VERSION ""

NS_ :

BS_:

BU_: HMI1 HMI2 VCU BMS MCU

BO_ 3221225472 VECTOR__INDEPENDENT_SIG_MSG: 0 Vector__XXX
 SG_ RangeReportVal : 16|8@1+ (1,0) [0|0] "km"  HMI1
 SG_ AverageReportVal : 24|8@1+ (1,0) [0|0] "km/kwh"  HMI1

BO_ 1984 HMI1Heartbeat: 2 HMI1
 SG_ HMI1Version : 0|16@1+ (1,0) [0|65535] ""  VCU

BO_ 1968 VCUHeartbeat: 2 VCU
 SG_ VCUVersion : 0|16@1+ (1,0) [0|65535] "" Vector__XXX

BO_ 2000 HMI2Heartbeat: 2 HMI2
 SG_ HMI2Version : 0|16@1+ (1,0) [0|65535] ""  VCU

BO_ 42 VCUSwitchControl: 8 VCU
 SG_ ABSState : 0|1@1+ (1,0) [0|1] ""  HMI1
 SG_ MirroringState : 1|1@1+ (1,0) [0|1] ""  HMI1
 SG_ LampState : 2|1@1+ (1,0) [0|1] ""  HMI1
 SG_ ErrorState : 3|1@1+ (1,0) [0|1] ""  HMI1
 SG_ OverheatState : 4|1@1+ (1,0) [0|1] ""  HMI1
 SG_ FingerState : 5|1@1+ (1,0) [0|1] ""  HMI1
 SG_ RemoteState : 6|1@1+ (1,0) [0|1] ""  HMI1
 SG_ DaylightState : 7|1@1+ (1,0) [0|1] ""  HMI1
 SG_ SeinLeftState : 8|1@1+ (1,0) [0|1] ""  HMI1
 SG_ SeinRightState : 9|1@1+ (1,0) [0|1] ""  HMI1
 SG_ HbarReverseState : 10|1@1+ (1,0) [0|1] ""  HMI1
 SG_ DriveMode : 16|2@1+ (1,0) [0|2] ""  HMI1
 SG_ TripMode : 18|2@1+ (1,0) [0|2] ""  HMI1
 SG_ ReportMode : 20|1@1+ (1,0) [0|1] ""  HMI1
 SG_ ModeState : 21|2@1+ (1,0) [0|2] ""  HMI1
 SG_ ModeHide : 23|1@1+ (1,0) [0|1] ""  HMI1
 SG_ SpeedVal : 24|8@1+ (1,0) [0|0] "km/h"  HMI1
 SG_ DiscurVal : 32|8@1+ (1,0) [0|0] "A"  HMI1
 SG_ NetSignalVal : 48|8@1+ (1,0) [0|100] "%"  HMI1
 SG_ BMSSocVal : 40|8@1+ (1,0) [0|100] "%"  HMI1
 SG_ VehicleState : 56|8@1- (1,0) [0|0] "" Vector__XXX
 SG_ BMSRun : 11|1@1+ (1,0) [0|0] "" Vector__XXX
 SG_ MCURun : 12|1@1+ (1,0) [0|0] "" Vector__XXX
 SG_ FGRRegisterBlink : 13|1@1+ (1,0) [0|0] "" Vector__XXX
 SG_ FGRRegisterError : 14|1@1+ (1,0) [0|0] "" Vector__XXX

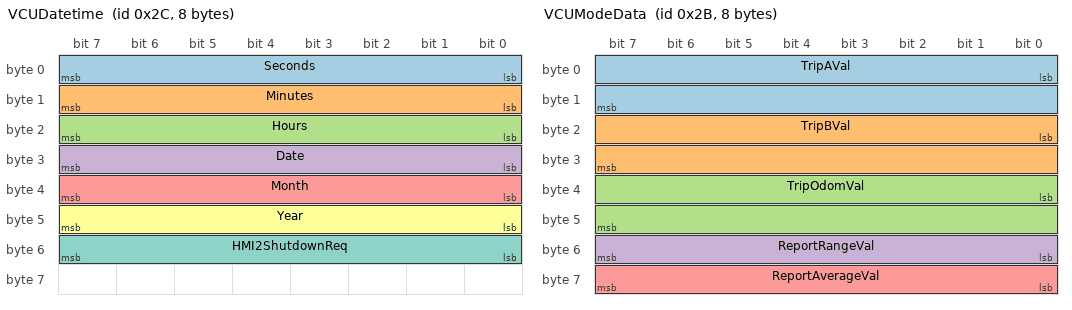
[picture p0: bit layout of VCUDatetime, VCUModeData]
BO_ 44 VCUDatetime: 8 VCU
 SG_ Seconds : 0|8@1+ (1,0) [0|60] ""  HMI2
 SG_ Minutes : 8|8@1+ (1,0) [0|60] ""  HMI2
 SG_ Hours : 16|8@1+ (1,0) [0|24] ""  HMI2
 SG_ Date : 24|8@1+ (1,0) [0|31] ""  HMI2
 SG_ Month : 32|8@1+ (1,0) [0|12] ""  HMI2
 SG_ Year : 40|8@1+ (1,0) [0|0] ""  HMI2
 SG_ HMI2ShutdownReq : 48|8@1+ (1,0) [0|1] ""  HMI2

BO_ 43 VCUModeData: 8 VCU
 SG_ TripAVal : 0|16@1+ (1,0) [0|0] "km"  HMI1
 SG_ TripBVal : 16|16@1+ (1,0) [0|0] "km"  HMI1
 SG_ TripOdomVal : 32|16@1+ (1,0) [0|0] "km"  HMI1
 SG_ ReportRangeVal : 48|8@1+ (1,0) [0|0] "km" Vector__XXX
 SG_ ReportAverageVal : 56|8@1+ (1,0) [0|0] "km/kwh" Vector__XXX

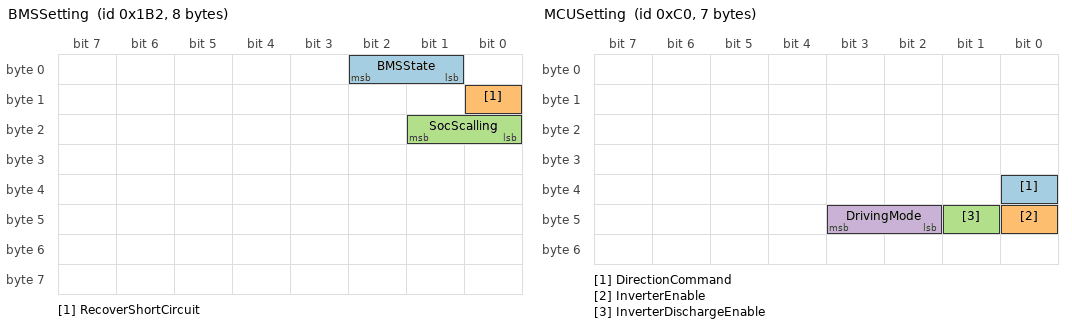
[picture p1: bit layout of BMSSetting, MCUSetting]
BO_ 434 BMSSetting: 8 VCU
 SG_ BMSState : 1|2@1+ (1,0) [0|3] ""  BMS
 SG_ RecoverShortCircuit : 8|1@1+ (1,0) [0|1] ""  BMS
 SG_ SocScalling : 16|2@1+ (1,0) [0|3] ""  BMS

BO_ 192 MCUSetting: 7 VCU
 SG_ DirectionCommand : 32|1@1+ (1,0) [0|0] ""  MCU
 SG_ InverterEnable : 40|1@1+ (1,0) [0|0] ""  MCU
 SG_ InverterDischargeEnable : 41|1@1+ (1,0) [0|0] ""  MCU
 SG_ DrivingMode : 42|2@1+ (1,0) [0|0] ""  MCU

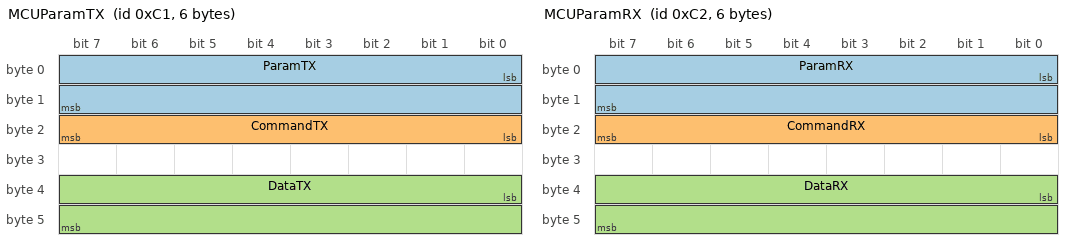
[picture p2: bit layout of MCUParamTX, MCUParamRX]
BO_ 193 MCUParamTX: 6 VCU
 SG_ ParamTX : 0|16@1+ (1,0) [0|0] ""  MCU
 SG_ CommandTX : 16|8@1+ (1,0) [0|0] ""  MCU
 SG_ DataTX : 32|16@1+ (1,0) [0|0] ""  MCU

BO_ 194 MCUParamRX: 6 MCU
 SG_ ParamRX : 0|16@1+ (1,0) [0|0] ""  VCU
 SG_ CommandRX : 16|8@1+ (1,0) [0|0] ""  VCU
 SG_ DataRX : 32|16@1+ (1,0) [0|0] ""  VCU

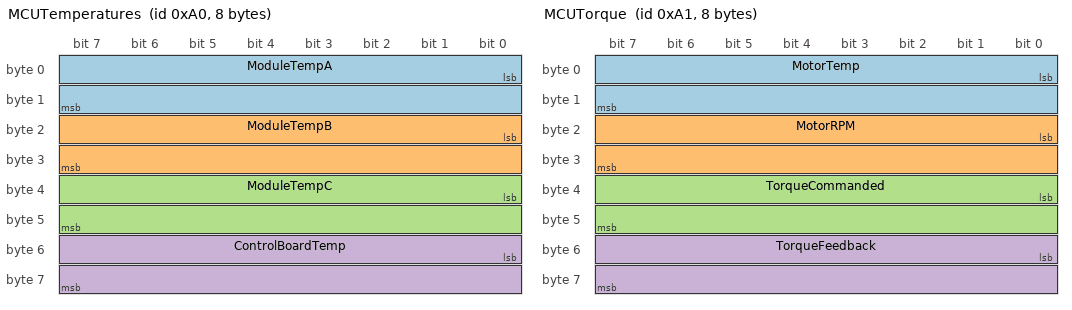
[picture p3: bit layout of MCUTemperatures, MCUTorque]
BO_ 160 MCUTemperatures: 8 MCU
 SG_ ModuleTempA : 0|16@1- (0.1,0) [0|0] "Celcius"  VCU
 SG_ ModuleTempB : 16|16@1- (0.1,0) [0|0] "Celcius"  VCU
 SG_ ModuleTempC : 32|16@1- (0.1,0) [0|0] "Celcius"  VCU
 SG_ ControlBoardTemp : 48|16@1- (0.1,0) [0|0] "Celcius"  VCU

BO_ 161 MCUTorque: 8 MCU
 SG_ MotorTemp : 0|16@1- (0.1,0) [0|0] "Celcius"  VCU
 SG_ MotorRPM : 16|16@1- (1,0) [0|0] "rpm"  VCU
 SG_ TorqueCommanded : 32|16@1- (0.1,0) [0|0] "Nm"  VCU
 SG_ TorqueFeedback : 48|16@1- (0.1,0) [0|0] "Nm"  VCU

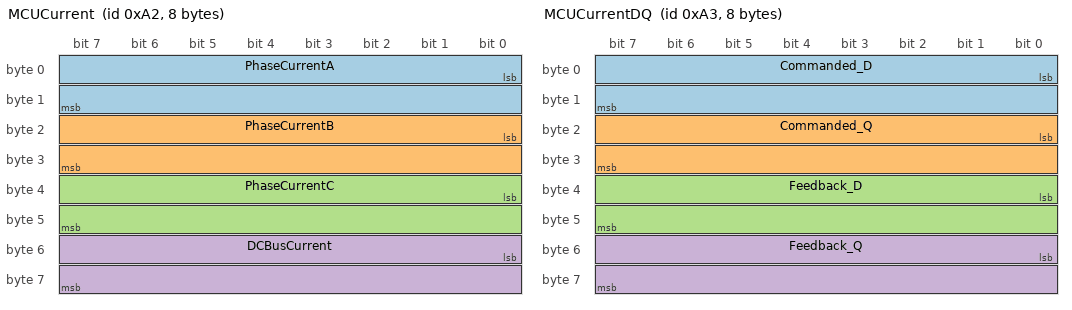
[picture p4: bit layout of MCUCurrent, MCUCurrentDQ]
BO_ 162 MCUCurrent: 8 MCU
 SG_ PhaseCurrentA : 0|16@1- (0.1,0) [0|0] "A"  VCU
 SG_ PhaseCurrentB : 16|16@1- (0.1,0) [0|0] "A"  VCU
 SG_ PhaseCurrentC : 32|16@1- (0.1,0) [0|0] "A"  VCU
 SG_ DCBusCurrent : 48|16@1- (0.1,0) [0|0] "A"  VCU

BO_ 163 MCUCurrentDQ: 8 MCU
 SG_ Commanded_D : 0|16@1- (0.1,0) [0|0] "A"  VCU
 SG_ Commanded_Q : 16|16@1- (0.1,0) [0|0] "A"  VCU
 SG_ Feedback_D : 32|16@1- (0.1,0) [0|0] "A"  VCU
 SG_ Feedback_Q : 48|16@1- (0.1,0) [0|0] "A"  VCU

BO_ 164 MCUFaultCodes: 8 MCU
 SG_ FaultPOST : 0|32@1+ (1,0) [0|0] ""  VCU
 SG_ FaultRUN : 32|32@1+ (1,0) [0|0] ""  VCU

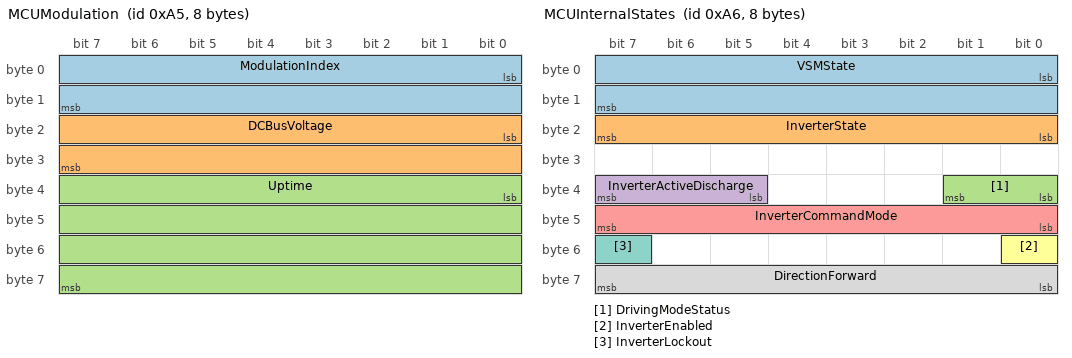
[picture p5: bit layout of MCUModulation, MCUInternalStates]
BO_ 165 MCUModulation: 8 MCU
 SG_ ModulationIndex : 0|16@1- (0.001,0) [0|0] ""  VCU
 SG_ DCBusVoltage : 16|16@1- (0.1,0) [0|0] "Volt"  VCU
 SG_ Uptime : 32|32@1+ (0.003,0) [0|0] "Second"  VCU

BO_ 166 MCUInternalStates: 8 MCU
 SG_ VSMState : 0|16@1+ (1,0) [0|0] ""  VCU
 SG_ InverterState : 16|8@1+ (1,0) [0|0] ""  VCU
 SG_ DrivingModeStatus : 32|2@1+ (1,0) [0|0] ""  VCU
 SG_ InverterActiveDischarge : 37|3@1+ (1,0) [0|0] ""  VCU
 SG_ InverterCommandMode : 40|8@1+ (1,0) [0|0] ""  VCU
 SG_ InverterEnabled : 48|1@1+ (1,0) [0|0] ""  VCU
 SG_ InverterLockout : 55|1@1+ (1,0) [0|0] ""  VCU
 SG_ DirectionForward : 56|8@1+ (1,0) [0|0] ""  VCU

BO_ 26 DFUProgress: 8 VCU
 SG_ DeviceType : 0|32@1+ (1,0) [0|0] ""  HMI1
 SG_ Progress : 32|32@1- (1,0) [0|0] "%"  HMI1

BO_ 27 DFUCrc: 4 HMI1
 SG_ CrcOldVal : 0|32@1+ (1,0) [0|0] ""  VCU

BO_ 28 DFUPra: 4 VCU
 SG_ FirmwareSize : 0|32@1+ (1,0) [0|0] ""  HMI1

BO_ 29 DFUInit: 6 VCU
 SG_ FirmwareOffset : 0|32@1+ (1,0) [0|0] ""  HMI1
 SG_ BlockOffset : 32|16@1+ (1,0) [0|0] ""  HMI1

BO_ 30 DFURun: 8 VCU
 SG_ SubBlockOffset : 0|16@1+ (1,0) [0|0] ""  HMI1
 SG_ FirmwareData : 32|32@1+ (1,0) [0|0] ""  HMI1

BO_ 31 DFUPasca: 4 VCU
 SG_ CrcNewVal : 0|32@1+ (1,0) [0|0] ""  HMI1

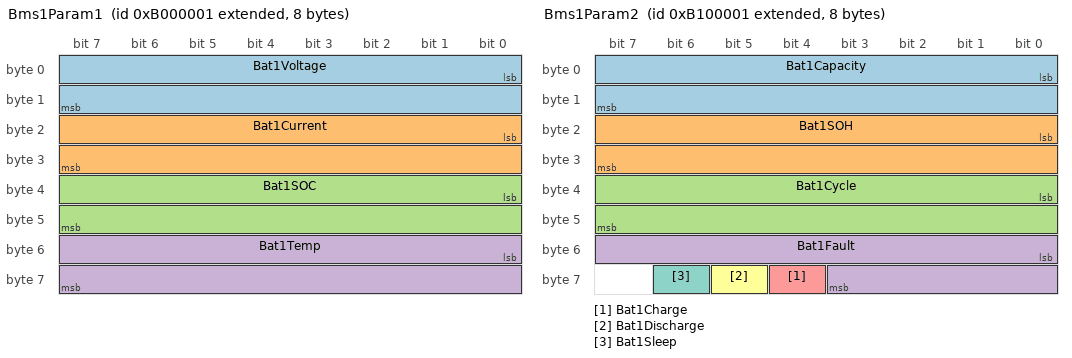
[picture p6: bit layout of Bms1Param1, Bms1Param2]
BO_ 2332033025 Bms1Param1: 8 BMS
 SG_ Bat1Voltage : 0|16@1+ (0.01,0) [0|0] "V" Vector__XXX
 SG_ Bat1Current : 16|16@1+ (0.1,0) [0|0] "A" Vector__XXX
 SG_ Bat1SOC : 32|16@1+ (1,0) [0|0] "%" Vector__XXX
 SG_ Bat1Temp : 48|16@1+ (1,-40) [0|0] "C" Vector__XXX

BO_ 2333081601 Bms1Param2: 8 BMS
 SG_ Bat1Capacity : 0|16@1+ (0.1,0) [0|0] "Ah" Vector__XXX
 SG_ Bat1SOH : 16|16@1+ (1,0) [0|0] "%" Vector__XXX
 SG_ Bat1Cycle : 32|16@1+ (1,0) [0|0] "" Vector__XXX
 SG_ Bat1Fault : 48|12@1+ (1,0) [0|0] "" Vector__XXX
 SG_ Bat1Charge : 60|1@1+ (1,0) [0|0] "" Vector__XXX
 SG_ Bat1Discharge : 61|1@1+ (1,0) [0|0] "" Vector__XXX
 SG_ Bat1Sleep : 62|1@1+ (1,0) [0|0] "" Vector__XXX

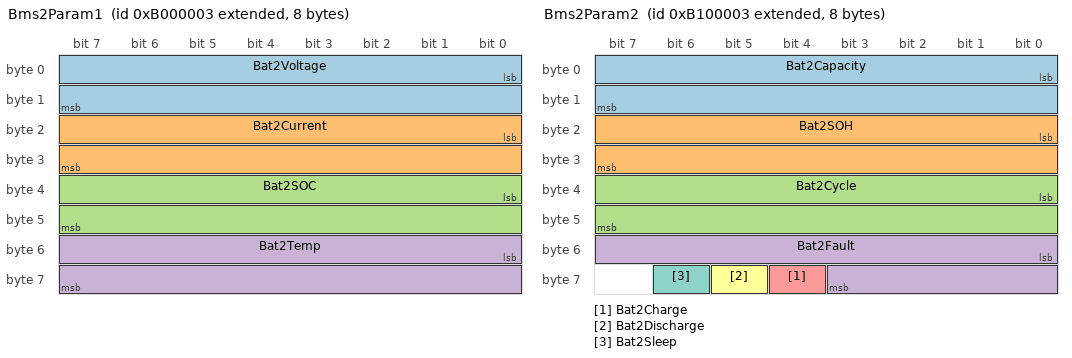
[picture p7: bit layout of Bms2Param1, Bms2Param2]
BO_ 2332033027 Bms2Param1: 8 BMS
 SG_ Bat2Voltage : 0|16@1+ (0.01,0) [0|0] "V" Vector__XXX
 SG_ Bat2Current : 16|16@1+ (0.1,0) [0|0] "A" Vector__XXX
 SG_ Bat2SOC : 32|16@1+ (1,0) [0|0] "%" Vector__XXX
 SG_ Bat2Temp : 48|16@1+ (1,-40) [0|0] "C" Vector__XXX

BO_ 2333081603 Bms2Param2: 8 BMS
 SG_ Bat2Capacity : 0|16@1+ (0.1,0) [0|0] "Ah" Vector__XXX
 SG_ Bat2SOH : 16|16@1+ (1,0) [0|0] "%" Vector__XXX
 SG_ Bat2Cycle : 32|16@1+ (1,0) [0|0] "" Vector__XXX
 SG_ Bat2Fault : 48|12@1+ (1,0) [0|0] "" Vector__XXX
 SG_ Bat2Charge : 60|1@1+ (1,0) [0|0] "" Vector__XXX
 SG_ Bat2Discharge : 61|1@1+ (1,0) [0|0] "" Vector__XXX
 SG_ Bat2Sleep : 62|1@1+ (1,0) [0|0] "" Vector__XXX

BA_DEF_ BO_  "GenMsgBackgroundColor" STRING ;
BA_DEF_ BO_  "GenMsgForegroundColor" STRING ;
BA_DEF_DEF_  "GenMsgBackgroundColor" "#ffffff";
BA_DEF_DEF_  "GenMsgForegroundColor" "#000000";
